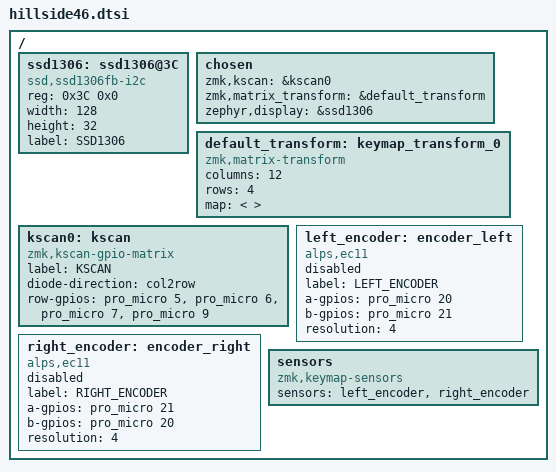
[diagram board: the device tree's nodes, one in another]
/*
 * Copyright (c) 2021-2022 The ZMK Contributors
 *
 * SPDX-License-Identifier: MIT
 */

#include <dt-bindings/zmk/matrix_transform.h>

 / {
    // Först definierar vi OLED-displayen (ssd1306@3C)
    ssd1306: ssd1306@3C {
        compatible = "ssd,ssd1306fb-i2c";
        reg = <0x3C 0x0>;  // Adressen för OLED-displayen och storlek
        width = <128>;
        height = <32>;
        label = "SSD1306";
    };

    // Nu refererar vi till display-noden
    chosen {
        zmk,kscan = &kscan0;
        zmk,matrix_transform = &default_transform;
        zephyr,display = &ssd1306;  // Referens till den definierade ssd1306-noden
    };

    default_transform: keymap_transform_0 {
        compatible = "zmk,matrix-transform";
        columns = <12>;
        rows = <4>;
        map = < /* tangentbordsmatrisens karta */ >;
    };

    kscan0: kscan {
        compatible = "zmk,kscan-gpio-matrix";
        label = "KSCAN";
        diode-direction = "col2row";
        row-gpios = <&pro_micro 5 (GPIO_ACTIVE_HIGH | GPIO_PULL_DOWN)>
                   , <&pro_micro 6 (GPIO_ACTIVE_HIGH | GPIO_PULL_DOWN)>
                   , <&pro_micro 7 (GPIO_ACTIVE_HIGH | GPIO_PULL_DOWN)>
                   , <&pro_micro 9 (GPIO_ACTIVE_HIGH | GPIO_PULL_DOWN)>;
    };

    left_encoder: encoder_left {
        compatible = "alps,ec11";
        label = "LEFT_ENCODER";
        a-gpios = <&pro_micro 20 (GPIO_ACTIVE_HIGH | GPIO_PULL_UP)>;
        b-gpios = <&pro_micro 21 (GPIO_ACTIVE_HIGH | GPIO_PULL_UP)>;
        resolution = <4>;
        status = "disabled";
    };

    right_encoder: encoder_right {
        compatible = "alps,ec11";
        label = "RIGHT_ENCODER";
        a-gpios = <&pro_micro 21 (GPIO_ACTIVE_HIGH | GPIO_PULL_UP)>;
        b-gpios = <&pro_micro 20 (GPIO_ACTIVE_HIGH | GPIO_PULL_UP)>;
        resolution = <4>;
        status = "disabled";
    };

    sensors {
        compatible = "zmk,keymap-sensors";
        sensors = <&left_encoder &right_encoder>;
    };
};
